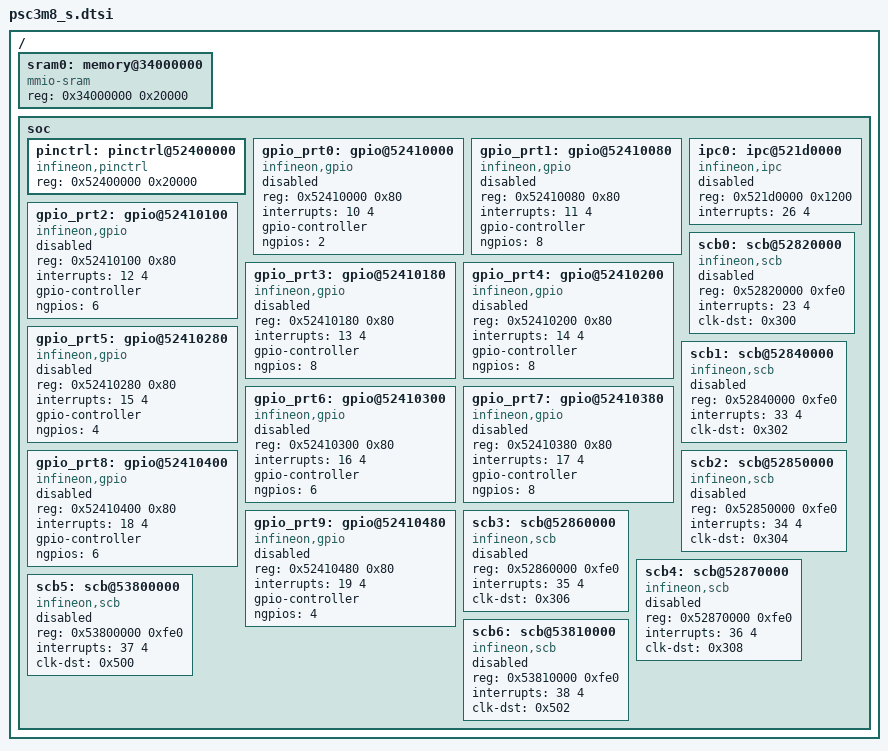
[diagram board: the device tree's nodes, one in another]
/*
 * SPDX-FileCopyrightText: Copyright (c) 2026 Infineon Technologies AG,
 * SPDX-FileCopyrightText: or an affiliate of Infineon Technologies AG. All rights reserved.
 *
 * SPDX-License-Identifier: Apache-2.0
 */

#include <mem.h>
#include "psc3m8.cm33.dtsi"

/ {
	sram0: memory@34000000 {
		compatible = "mmio-sram";
		reg = <0x34000000 0x20000>;
	};

	soc {
		pinctrl: pinctrl@52400000 {
			compatible = "infineon,pinctrl";
			reg = <0x52400000 0x20000>;
		};

		gpio_prt0: gpio@52410000 {
			compatible = "infineon,gpio";
			reg = <0x52410000 0x80>;
			interrupts = <10 4>;
			gpio-controller;
			ngpios = <2>;
			status = "disabled";
			#gpio-cells = <2>;
		};

		gpio_prt1: gpio@52410080 {
			compatible = "infineon,gpio";
			reg = <0x52410080 0x80>;
			interrupts = <11 4>;
			gpio-controller;
			ngpios = <8>;
			status = "disabled";
			#gpio-cells = <2>;
		};

		gpio_prt2: gpio@52410100 {
			compatible = "infineon,gpio";
			reg = <0x52410100 0x80>;
			interrupts = <12 4>;
			gpio-controller;
			ngpios = <6>;
			status = "disabled";
			#gpio-cells = <2>;
		};

		gpio_prt3: gpio@52410180 {
			compatible = "infineon,gpio";
			reg = <0x52410180 0x80>;
			interrupts = <13 4>;
			gpio-controller;
			ngpios = <8>;
			status = "disabled";
			#gpio-cells = <2>;
		};

		gpio_prt4: gpio@52410200 {
			compatible = "infineon,gpio";
			reg = <0x52410200 0x80>;
			interrupts = <14 4>;
			gpio-controller;
			ngpios = <8>;
			status = "disabled";
			#gpio-cells = <2>;
		};

		gpio_prt5: gpio@52410280 {
			compatible = "infineon,gpio";
			reg = <0x52410280 0x80>;
			interrupts = <15 4>;
			gpio-controller;
			ngpios = <4>;
			status = "disabled";
			#gpio-cells = <2>;
		};

		gpio_prt6: gpio@52410300 {
			compatible = "infineon,gpio";
			reg = <0x52410300 0x80>;
			interrupts = <16 4>;
			gpio-controller;
			ngpios = <6>;
			status = "disabled";
			#gpio-cells = <2>;
		};

		gpio_prt7: gpio@52410380 {
			compatible = "infineon,gpio";
			reg = <0x52410380 0x80>;
			interrupts = <17 4>;
			gpio-controller;
			ngpios = <8>;
			status = "disabled";
			#gpio-cells = <2>;
		};

		gpio_prt8: gpio@52410400 {
			compatible = "infineon,gpio";
			reg = <0x52410400 0x80>;
			interrupts = <18 4>;
			gpio-controller;
			ngpios = <6>;
			status = "disabled";
			#gpio-cells = <2>;
		};

		gpio_prt9: gpio@52410480 {
			compatible = "infineon,gpio";
			reg = <0x52410480 0x80>;
			interrupts = <19 4>;
			gpio-controller;
			ngpios = <4>;
			status = "disabled";
			#gpio-cells = <2>;
		};

		ipc0: ipc@521d0000 {
			compatible = "infineon,ipc";
			reg = <0x521d0000 0x1200>;
			interrupts = <26 4>;
			status = "disabled";
			#ipc-config-cells = <2>;
		};

		scb0: scb@52820000 {
			compatible = "infineon,scb";
			reg = <0x52820000 0xfe0>;
			interrupts = <23 4>;
			clk-dst = <0x300>;
			status = "disabled";
		};

		scb1: scb@52840000 {
			compatible = "infineon,scb";
			reg = <0x52840000 0xfe0>;
			interrupts = <33 4>;
			clk-dst = <0x302>;
			status = "disabled";
		};

		scb2: scb@52850000 {
			compatible = "infineon,scb";
			reg = <0x52850000 0xfe0>;
			interrupts = <34 4>;
			clk-dst = <0x304>;
			status = "disabled";
		};

		scb3: scb@52860000 {
			compatible = "infineon,scb";
			reg = <0x52860000 0xfe0>;
			interrupts = <35 4>;
			clk-dst = <0x306>;
			status = "disabled";
		};

		scb4: scb@52870000 {
			compatible = "infineon,scb";
			reg = <0x52870000 0xfe0>;
			interrupts = <36 4>;
			clk-dst = <0x308>;
			status = "disabled";
		};

		scb5: scb@53800000 {
			compatible = "infineon,scb";
			reg = <0x53800000 0xfe0>;
			interrupts = <37 4>;
			clk-dst = <0x500>;
			status = "disabled";
		};

		scb6: scb@53810000 {
			compatible = "infineon,scb";
			reg = <0x53810000 0xfe0>;
			interrupts = <38 4>;
			clk-dst = <0x502>;
			status = "disabled";
		};
	};
};
